# STM32L4x1 register map
File version: 1.0
Registers are 32-bit, read-write, reset 0x0 unless marked. A register's access mark holds for its fields unless they carry their own. Offsets are from the block's base; [hi:lo] are bit positions; {n}, {i} and the like mark numbered series.

## SPI1 — Serial peripheral interface/Inter-IC sound
Base 0x40013000
Same registers: SPI2 0x40003800, SPI3 0x40003C00
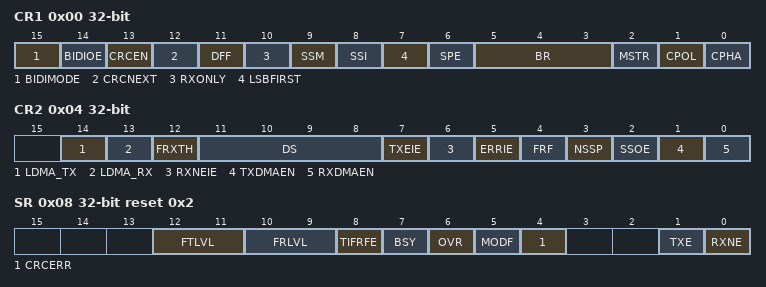
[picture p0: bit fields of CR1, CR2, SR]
0x00 CR1 — control register 1
  [15] BIDIMODE — Bidirectional data mode enable
  [14] BIDIOE — Output enable in bidirectional mode
  [13] CRCEN — Hardware CRC calculation enable
  [12] CRCNEXT — CRC transfer next
  [11] DFF — Data frame format
  [10] RXONLY — Receive only
  [9] SSM — Software slave management
  [8] SSI — Internal slave select
  [7] LSBFIRST — Frame format
  [6] SPE — SPI enable
  [5:3] BR — Baud rate control
  [2] MSTR — Master selection
  [1] CPOL — Clock polarity
  [0] CPHA — Clock phase
0x04 CR2 — control register 2
  [14] LDMA_TX — Last DMA transfer for transmission
  [13] LDMA_RX — Last DMA transfer for reception
  [12] FRXTH — FIFO reception threshold
  [11:8] DS — Data size
  [7] TXEIE — Tx buffer empty interrupt enable
  [6] RXNEIE — RX buffer not empty interrupt enable
  [5] ERRIE — Error interrupt enable
  [4] FRF — Frame format
  [3] NSSP — NSS pulse management
  [2] SSOE — SS output enable
  [1] TXDMAEN — Tx buffer DMA enable
  [0] RXDMAEN — Rx buffer DMA enable
0x08 SR access per field reset 0x2 — status register
  [12:11] FTLVL ro — FIFO transmission level
  [10:9] FRLVL ro — FIFO reception level
  [8] TIFRFE ro — TI frame format error
  [7] BSY ro — Busy flag
  [6] OVR ro — Overrun flag
  [5] MODF ro — Mode fault
  [4] CRCERR rw — CRC error flag
  [1] TXE ro — Transmit buffer empty
  [0] RXNE ro — Receive buffer not empty
0x0C DR — data register
  [15:0] DR — Data register
0x10 CRCPR reset 0x7 — CRC polynomial register
  [15:0] CRCPOLY
0x14 RXCRCR ro — RX CRC register
  [15:0] RxCRC
0x18 TXCRCR ro — TX CRC register
  [15:0] TxCRC

## EXTI — External interrupt/event controller
Base 0x40010400
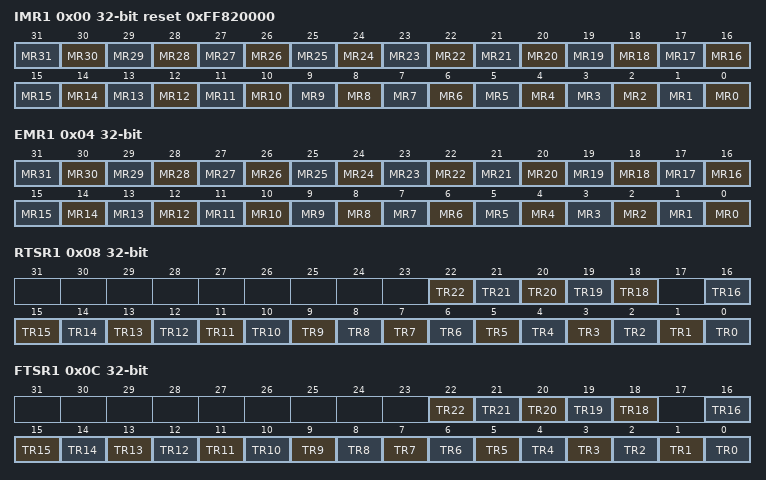
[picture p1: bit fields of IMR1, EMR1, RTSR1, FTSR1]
0x00 IMR1 reset 0xFF820000 — Interrupt mask register
  [n] MR{n} (n=0..31) — Interrupt Mask on line {n}
0x04 EMR1 — Event mask register
  [n] MR{n} (n=0..31) — Event Mask on line {n}
0x08 RTSR1 — Rising Trigger selection register
  [n] TR{n} (n=18..22) — Rising trigger event configuration of line {n}
  [n] TR{n} (n=0..16) — Rising trigger event configuration of line {n}
0x0C FTSR1 — Falling Trigger selection register
  [n] TR{n} (n=18..22) — Falling trigger event configuration of line {n}
  [n] TR{n} (n=0..16) — Falling trigger event configuration of line {n}
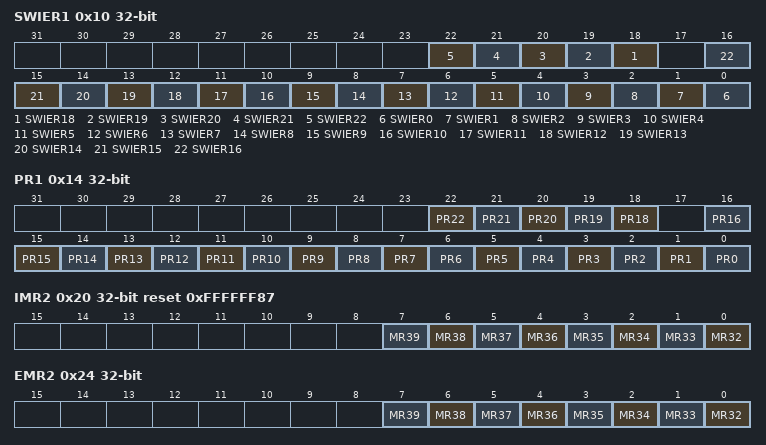
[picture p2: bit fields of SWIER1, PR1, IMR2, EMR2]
0x10 SWIER1 — Software interrupt event register
  [n] SWIER{n} (n=18..22) — Software Interrupt on line {n}
  [n] SWIER{n} (n=0..16) — Software Interrupt on line {n}
0x14 PR1 — Pending register
  [n] PR{n} (n=18..22) — Pending bit {n}
  [n] PR{n} (n=0..16) — Pending bit {n}
0x20 IMR2 reset 0xFFFFFF87 — Interrupt mask register
  [n-32] MR{n} (n=32..39) — Interrupt Mask on external/internal line {n}
0x24 EMR2 — Event mask register
  [n-32] MR{n} (n=32..39) — Event mask on external/internal line {n}
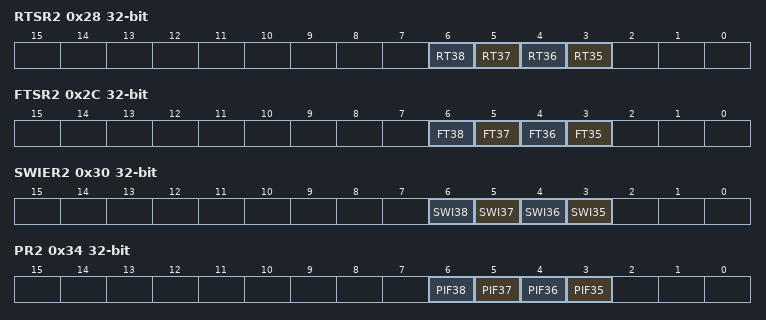
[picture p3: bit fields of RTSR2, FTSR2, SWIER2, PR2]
0x28 RTSR2 — Rising Trigger selection register
  [n-32] RT{n} (n=35..38) — Rising trigger event configuration bit of line {n}
0x2C FTSR2 — Falling Trigger selection register
  [n-32] FT{n} (n=35..38) — Falling trigger event configuration bit of line {n}
0x30 SWIER2 — Software interrupt event register
  [n-32] SWI{n} (n=35..38) — Software interrupt on line {n}
0x34 PR2 — Pending register
  [n-32] PIF{n} (n=35..38) — Pending interrupt flag on line {n}

## VREFBUF — Voltage reference buffer
Base 0x40010030
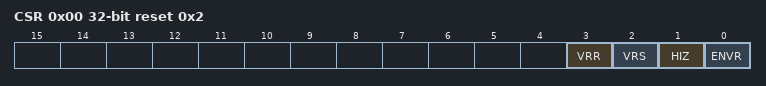
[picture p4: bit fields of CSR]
0x00 CSR access per field reset 0x2 — VREF control and status register
  [3] VRR ro — Voltage reference buffer ready
  [2] VRS rw — Voltage reference scale
  [1] HIZ rw — High impedance mode
  [0] ENVR rw — Voltage reference buffer enable
0x04 CCR — calibration control register
  [5:0] TRIM — Trimming code

## CAN1 — Controller area network
Base 0x40006400
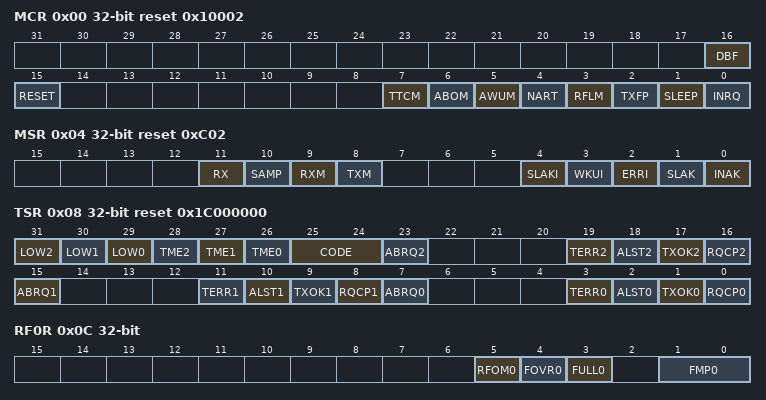
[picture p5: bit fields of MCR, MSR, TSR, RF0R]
0x00 MCR reset 0x10002 — master control register
  [16] DBF, [15] RESET, [7] TTCM, [6] ABOM, [5] AWUM, [4] NART, [3] RFLM, [2] TXFP, [1] SLEEP, [0] INRQ
0x04 MSR access per field reset 0xC02 — master status register
  [11] RX ro, [10] SAMP ro, [9] RXM ro, [8] TXM ro, [4] SLAKI rw, [3] WKUI rw, [2] ERRI rw, [1] SLAK ro, [0] INAK ro
0x08 TSR access per field reset 0x1C000000 — transmit status register
  [31] LOW2 ro — Lowest priority flag for mailbox 2
  [30] LOW1 ro — Lowest priority flag for mailbox 1
  [29] LOW0 ro — Lowest priority flag for mailbox 0
  [28] TME2 ro — Lowest priority flag for mailbox 2
  [27] TME1 ro — Lowest priority flag for mailbox 1
  [26] TME0 ro — Lowest priority flag for mailbox 0
  [25:24] CODE ro
  [23] ABRQ2 rw
  [19] TERR2 rw
  [18] ALST2 rw
  [17] TXOK2 rw
  [16] RQCP2 rw
  [15] ABRQ1 rw
  [11] TERR1 rw
  [10] ALST1 rw
  [9] TXOK1 rw
  [8] RQCP1 rw
  [7] ABRQ0 rw
  [3] TERR0 rw
  [2] ALST0 rw
  [1] TXOK0 rw
  [0] RQCP0 rw
0x0C RF0R access per field — receive FIFO 0 register
  [5] RFOM0 rw, [4] FOVR0 rw, [3] FULL0 rw, [1:0] FMP0 ro
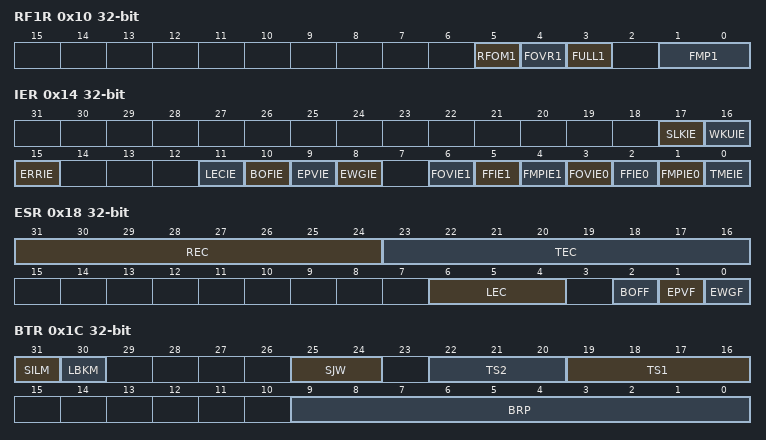
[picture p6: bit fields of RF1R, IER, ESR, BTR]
0x10 RF1R access per field — receive FIFO 1 register
  [5] RFOM1 rw, [4] FOVR1 rw, [3] FULL1 rw, [1:0] FMP1 ro
0x14 IER — interrupt enable register
  [17] SLKIE, [16] WKUIE, [15] ERRIE, [11] LECIE, [10] BOFIE, [9] EPVIE, [8] EWGIE, [6] FOVIE1, [5] FFIE1, [4] FMPIE1, [3] FOVIE0, [2] FFIE0, [1] FMPIE0, [0] TMEIE
0x18 ESR access per field — interrupt enable register
  [31:24] REC ro, [23:16] TEC ro, [6:4] LEC rw, [2] BOFF ro, [1] EPVF ro, [0] EWGF ro
0x1C BTR — bit timing register
  [31] SILM, [30] LBKM, [25:24] SJW, [22:20] TS2, [19:16] TS1, [9:0] BRP
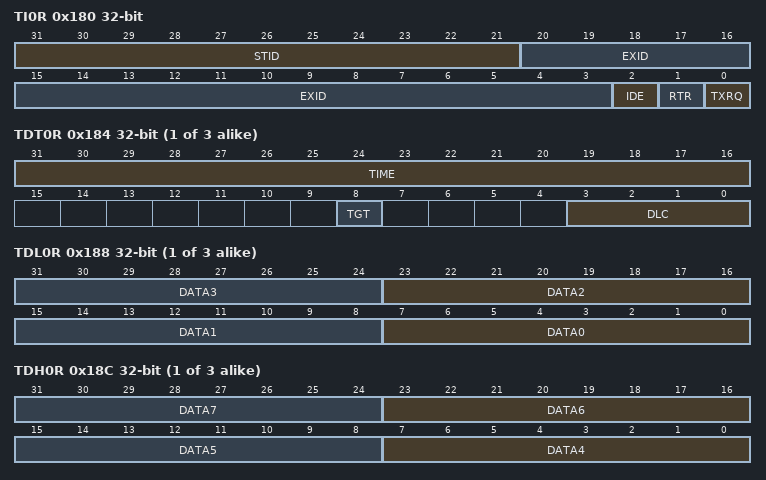
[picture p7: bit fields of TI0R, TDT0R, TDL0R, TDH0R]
0x180 TI0R — TX mailbox identifier register
  [31:21] STID, [20:3] EXID, [2] IDE, [1] RTR, [0] TXRQ
{0x184+0x10*i} TDT{i}R (i=0..2) — mailbox data length control and time stamp register
  [31:16] TIME, [8] TGT, [3:0] DLC
{0x188+0x10*i} TDL{i}R (i=0..2) — mailbox data low register
  [8n+7:8n] DATA{n} (n=0..3)
{0x18C+0x10*i} TDH{i}R (i=0..2) — mailbox data high register
  [8n-25:8n-32] DATA{n} (n=4..7)
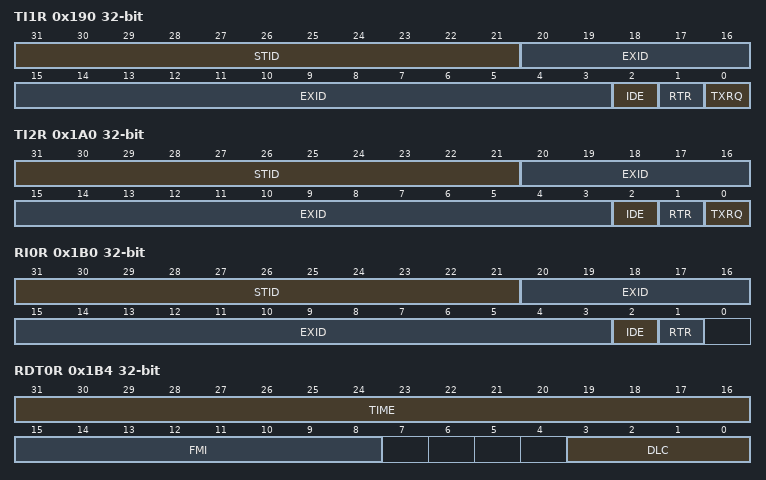
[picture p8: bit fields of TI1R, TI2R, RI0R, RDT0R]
0x190 TI1R — mailbox identifier register
  [31:21] STID, [20:3] EXID, [2] IDE, [1] RTR, [0] TXRQ
0x1A0 TI2R — mailbox identifier register
  [31:21] STID, [20:3] EXID, [2] IDE, [1] RTR, [0] TXRQ
0x1B0 RI0R ro — receive FIFO mailbox identifier register
  [31:21] STID, [20:3] EXID, [2] IDE, [1] RTR
0x1B4 RDT0R ro — mailbox data high register
  [31:16] TIME, [15:8] FMI, [3:0] DLC
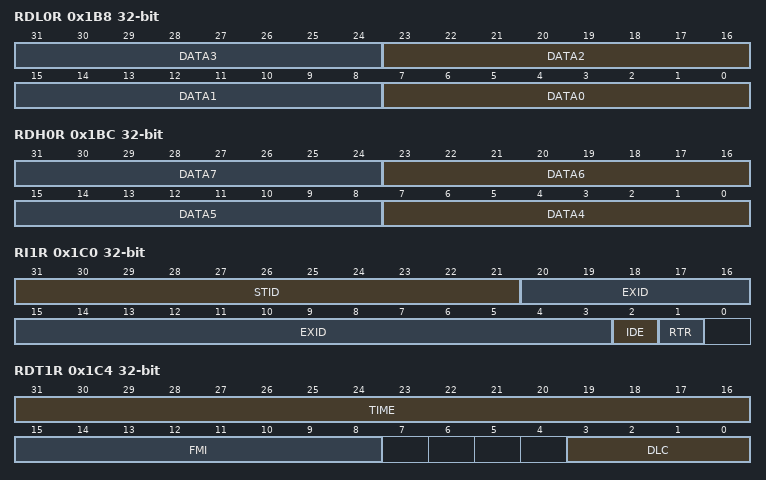
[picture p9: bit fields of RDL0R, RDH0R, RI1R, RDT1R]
0x1B8 RDL0R ro — mailbox data high register
  [8n+7:8n] DATA{n} (n=0..3)
0x1BC RDH0R ro — receive FIFO mailbox data high register
  [8n-25:8n-32] DATA{n} (n=4..7)
0x1C0 RI1R ro — mailbox data high register
  [31:21] STID, [20:3] EXID, [2] IDE, [1] RTR
0x1C4 RDT1R ro — mailbox data high register
  [31:16] TIME, [15:8] FMI, [3:0] DLC
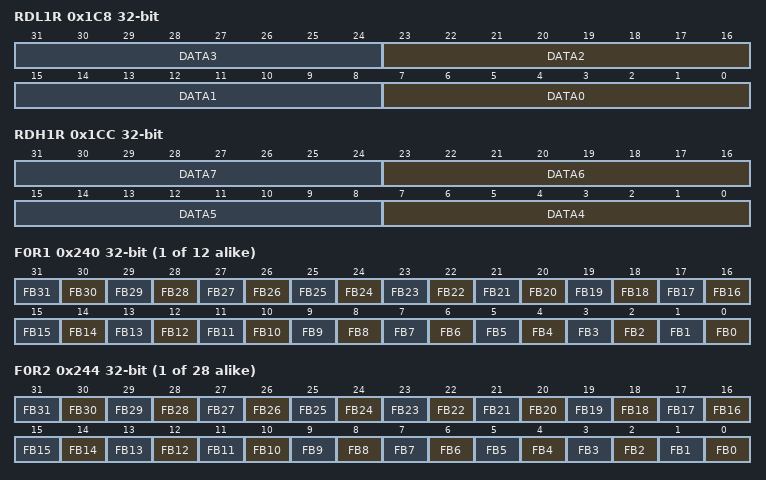
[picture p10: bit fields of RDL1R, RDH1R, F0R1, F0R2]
0x1C8 RDL1R ro — mailbox data high register
  [8n+7:8n] DATA{n} (n=0..3)
0x1CC RDH1R ro — mailbox data high register
  [8n-25:8n-32] DATA{n} (n=4..7)
{0x240+8i} F{i}R1 (i=0..11) — Filter bank {i} register 1
  [n] FB{n} (n=0..31) — Filter bits
{0x244+8i} F{i}R2 (i=0..27) — Filter bank {i} register 2
  [n] FB{n} (n=0..31) — Filter bits
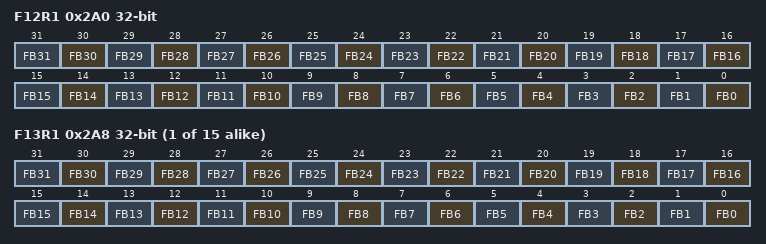
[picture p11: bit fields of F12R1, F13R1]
0x2A0 F12R1 — Filter bank 4 register 1
  [n] FB{n} (n=0..31) — Filter bits
{0x240+8i} F{i}R1 (i=13..27) — Filter bank {i} register 1
  [n] FB{n} (n=0..31) — Filter bits
